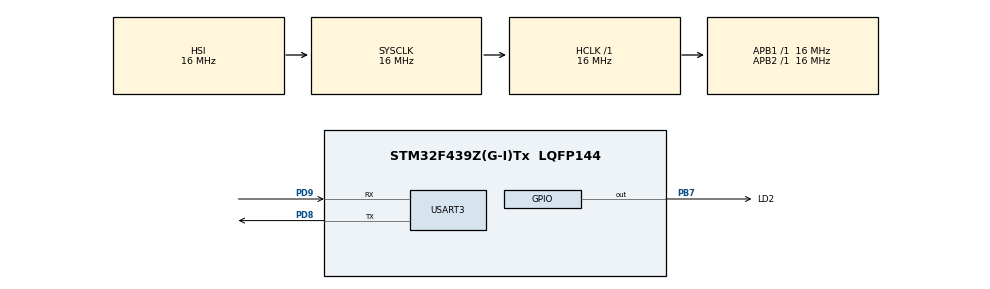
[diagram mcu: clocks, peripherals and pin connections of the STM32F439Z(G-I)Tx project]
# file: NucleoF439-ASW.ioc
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Mcu.Family=STM32F4
Mcu.Name=STM32F439Z(G-I)Tx
Mcu.Package=LQFP144
NVIC.PriorityGroup=NVIC_PRIORITYGROUP_4
PB7.GPIO_Label=LD2
PB7.Signal=GPIO_Output
PD8.Mode=Asynchronous
PD8.Signal=USART3_TX
PD9.Mode=Asynchronous
PD9.Signal=USART3_RX
ProjectManager.HeapSize=0x200
ProjectManager.StackSize=0x400
ProjectManager.TargetToolchain=STM32CubeIDE
RCC.AHBFreq_Value=16000000
RCC.APB1Freq_Value=16000000
RCC.APB2Freq_Value=16000000
RCC.CortexFreq_Value=16000000
RCC.HSE_VALUE=25000000
RCC.HSI_VALUE=16000000
RCC.LSE_VALUE=32768
RCC.SYSCLKFreq_VALUE=16000000
RCC.VCOOutputFreq_Value=192000000
USART3.VirtualMode=VM_ASYNC
board=custom

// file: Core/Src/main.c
/* USER CODE BEGIN Header */
/**
  ******************************************************************************
  * @file           : main.c
  * @brief          : Main program body
  ******************************************************************************
  * @attention
  *
  * Copyright (c) 2026 STMicroelectronics.
  * All rights reserved.
  *
  * This software is licensed under terms that can be found in the LICENSE file
  * in the root directory of this software component.
  * If no LICENSE file comes with this software, it is provided AS-IS.
  *
  ******************************************************************************
  */
/* USER CODE END Header */
#include "main.h"

/* USER CODE BEGIN Includes */

#include <stdio.h>
#include "input.h"
#include "flash.h"

/* USER CODE END Includes */

/* USER CODE BEGIN PD */
#define CMD_POLL_TIMEOUT_MS        50U   /* polling interval for incoming commands */
/* USER CODE END PD */

UART_HandleTypeDef huart3;

/* USER CODE BEGIN PV */
static uint8_t cmdDataBuf[1];
/* USER CODE END PV */

void SystemClock_Config(void);
static void MX_GPIO_Init(void);
static void MX_USART3_UART_Init(void);

/* USER CODE BEGIN 0 */

int _write(int fd, char *ptr, int len) {
	if (fd == 1 || fd == 2)
	    {
	        // Send debug output as ECSS DEBUG_LOG packet
	        if (sendDebugPacket(&huart3, ptr, len) == 0)
	            return len;
	        else
	            return -1;
	    }
	    return -1;
}

/* USER CODE END 0 */

int main(void)
{

  /* USER CODE BEGIN 1 */

  __enable_irq();

  /* USER CODE END 1 */

  /* MCU Configuration--------------------------------------------------------*/

  /* Reset of all peripherals, Initializes the Flash interface and the Systick. */
  HAL_Init();

  /* Configure the system clock */
  SystemClock_Config();

  /* Initialize all configured peripherals */
  MX_GPIO_Init();
  MX_USART3_UART_Init();
  /* USER CODE BEGIN 2 */

  HAL_Delay(200);
  printf("App STARTED\r\n");
  printf("Commands: 1 = OK (set NOMINAL + restart) | 2 = FAULT (restart without clearing status)\r\n");

  /* USER CODE END 2 */

  /* Infinite loop */
  /* USER CODE BEGIN WHILE */
  while (1)
  {
	  /* Blink LED */
	  HAL_GPIO_TogglePin(LD2_GPIO_Port, LD2_Pin);

	  /* Poll for an ECSS command packet (short timeout so blink timing stays ~1 s) */
	  ECSSPacketHeader hdr;
	  uint32_t blinkStart = HAL_GetTick();
	  while ((HAL_GetTick() - blinkStart) < 1000U)
	  {
		  int8_t rc = receivePacketHeaderWithTimeout(&huart3, &hdr, CMD_POLL_TIMEOUT_MS);
		  if (rc == 0)
		  {
			  /* Receive payload (1 byte expected) */
			  if (hdr.data_length > 0 && hdr.data_length <= sizeof(cmdDataBuf))
			  {
				  receivePacketData(&huart3, cmdDataBuf, hdr.data_length);
			  }

			  char cmd = (char)cmdDataBuf[0];

			  if (cmd == '1')
			  {
				  /* Simulate healthy operation: clear BOOT_ATTEMPTED → set NOMINAL */
				  printf("CMD 1: OK - setting status NOMINAL and restarting\r\n");
				  if (setBootloaderStatus(BOOTLOADER_STATUS_NOMINAL) != 0)
				  {
					  printf("Failed to set status, only restarting");
				  }
				  sendAckPacket(&huart3, hdr.sequence_count);
				  NVIC_SystemReset();
			  }
			  else if (cmd == '2')
			  {
				  /* Simulate fault: reset WITHOUT clearing BOOT_ATTEMPTED so BSW triggers rollback */
				  printf("CMD 2: FAULT - resetting without clearing status\r\n");
				  sendAckPacket(&huart3, hdr.sequence_count);
				  NVIC_SystemReset();
			  }
			  else
			  {
				  printf("Unknown command: %c\r\n", cmd);
				  sendNackPacket(&huart3, hdr.sequence_count, 15);
			  }
			  break; /* restart the 1 s blink cycle */
		  }
	  }
    /* USER CODE END WHILE */

  }
}

void SystemClock_Config(void)
{
  RCC_OscInitTypeDef RCC_OscInitStruct = {0};
  RCC_ClkInitTypeDef RCC_ClkInitStruct = {0};

  /** Configure the main internal regulator output voltage
  */
  __HAL_RCC_PWR_CLK_ENABLE();
  __HAL_PWR_VOLTAGESCALING_CONFIG(PWR_REGULATOR_VOLTAGE_SCALE3);

  /** Initializes the RCC Oscillators according to the specified parameters
  * in the RCC_OscInitTypeDef structure.
  */
  RCC_OscInitStruct.OscillatorType = RCC_OSCILLATORTYPE_HSI;
  RCC_OscInitStruct.HSIState = RCC_HSI_ON;
  RCC_OscInitStruct.HSICalibrationValue = RCC_HSICALIBRATION_DEFAULT;
  RCC_OscInitStruct.PLL.PLLState = RCC_PLL_NONE;
  if (HAL_RCC_OscConfig(&RCC_OscInitStruct) != HAL_OK)
  {
    Error_Handler();
  }

  /** Initializes the CPU, AHB and APB buses clocks
  */
  RCC_ClkInitStruct.ClockType = RCC_CLOCKTYPE_HCLK|RCC_CLOCKTYPE_SYSCLK
                              |RCC_CLOCKTYPE_PCLK1|RCC_CLOCKTYPE_PCLK2;
  RCC_ClkInitStruct.SYSCLKSource = RCC_SYSCLKSOURCE_HSI;
  RCC_ClkInitStruct.AHBCLKDivider = RCC_SYSCLK_DIV1;
  RCC_ClkInitStruct.APB1CLKDivider = RCC_HCLK_DIV1;
  RCC_ClkInitStruct.APB2CLKDivider = RCC_HCLK_DIV1;

  if (HAL_RCC_ClockConfig(&RCC_ClkInitStruct, FLASH_LATENCY_0) != HAL_OK)
  {
    Error_Handler();
  }
}

static void MX_USART3_UART_Init(void)
{

  huart3.Instance = USART3;
  huart3.Init.BaudRate = 115200;
  huart3.Init.WordLength = UART_WORDLENGTH_8B;
  huart3.Init.StopBits = UART_STOPBITS_1;
  huart3.Init.Parity = UART_PARITY_NONE;
  huart3.Init.Mode = UART_MODE_TX_RX;
  huart3.Init.HwFlowCtl = UART_HWCONTROL_NONE;
  huart3.Init.OverSampling = UART_OVERSAMPLING_16;
  if (HAL_UART_Init(&huart3) != HAL_OK)
  {
    Error_Handler();
  }

}

static void MX_GPIO_Init(void)
{
  GPIO_InitTypeDef GPIO_InitStruct = {0};

  /* GPIO Ports Clock Enable */
  __HAL_RCC_GPIOD_CLK_ENABLE();
  __HAL_RCC_GPIOB_CLK_ENABLE();

  /*Configure GPIO pin Output Level */
  HAL_GPIO_WritePin(LD2_GPIO_Port, LD2_Pin, GPIO_PIN_RESET);

  /*Configure GPIO pin : LD2_Pin */
  GPIO_InitStruct.Pin = LD2_Pin;
  GPIO_InitStruct.Mode = GPIO_MODE_OUTPUT_PP;
  GPIO_InitStruct.Pull = GPIO_NOPULL;
  GPIO_InitStruct.Speed = GPIO_SPEED_FREQ_LOW;
  HAL_GPIO_Init(LD2_GPIO_Port, &GPIO_InitStruct);

}

void Error_Handler(void)
{
  __disable_irq();
  while (1)
  {
  }
}
